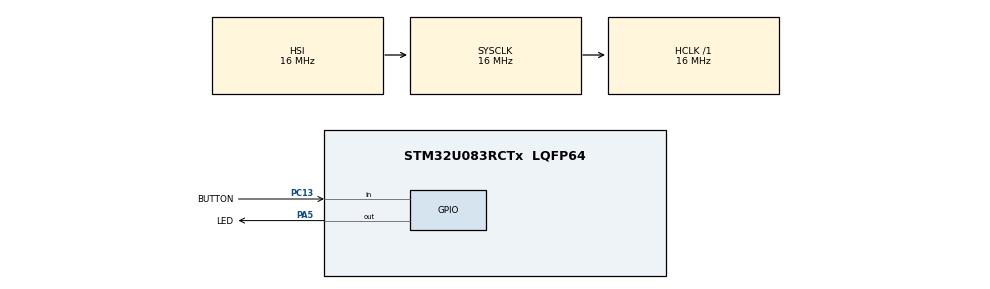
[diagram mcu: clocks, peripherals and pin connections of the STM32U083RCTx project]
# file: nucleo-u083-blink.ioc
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Mcu.Family=STM32U0
Mcu.Name=STM32U083RCTx
Mcu.Package=LQFP64
NVIC.PriorityGroup=NVIC_PRIORITYGROUP_2
PA5.GPIO_Label=LED
PA5.Signal=GPIO_Output
PC13.GPIO_Label=BUTTON
PC13.GPIO_PuPd=GPIO_PULLUP
PC13.Signal=GPIO_Input
ProjectManager.HeapSize=0x200
ProjectManager.StackSize=0x400
ProjectManager.TargetToolchain=Makefile
RCC.AHBFreq_Value=16000000
RCC.CortexFreq_Value=16000000
RCC.HCLKFreq_Value=16000000
RCC.HSE_VALUE=4000000
RCC.HSI48_VALUE=48000000
RCC.HSI_VALUE=16000000
RCC.LSE_VALUE=32768
RCC.MSI_VALUE=4000000
RCC.SYSCLKFreq_VALUE=16000000
RCC.VCOOutputFreq_Value=64000000
VP_PWR_VS_SECSignals.Mode=Security/Privilege
board=custom

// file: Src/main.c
/* USER CODE BEGIN Header */
/**
 ******************************************************************************
 * @file           : main.c
 * @brief          : Main program body
 ******************************************************************************
 * @attention
 *
 * Copyright (c) 2025 STMicroelectronics.
 * All rights reserved.
 *
 * This software is licensed under terms that can be found in the LICENSE file
 * in the root directory of this software component.
 * If no LICENSE file comes with this software, it is provided AS-IS.
 *
 ******************************************************************************
 */
/* USER CODE END Header */
#include "main.h"

#include "gpio.h"

/* USER CODE BEGIN Includes */
#include <stdbool.h>

/* USER CODE END Includes */

void SystemClock_Config(void);

int main(void) {

    /* MCU
     * Configuration--------------------------------------------------------*/

    /* Reset of all peripherals, Initializes the Flash interface and the
     * Systick. */
    HAL_Init();

    /* Configure the system clock */
    SystemClock_Config();

    /* Initialize all configured peripherals */
    MX_GPIO_Init();

    /* Infinite loop */
    while (1) {

        /* USER CODE BEGIN 3 */
        bool blink_faster = !HAL_GPIO_ReadPin(BUTTON_GPIO_Port, BUTTON_Pin);
        HAL_GPIO_TogglePin(LED_GPIO_Port, LED_Pin);
        HAL_Delay(blink_faster ? 100 : 250);
    }
    /* USER CODE END 3 */
}

void SystemClock_Config(void) {
    RCC_OscInitTypeDef RCC_OscInitStruct = {0};
    RCC_ClkInitTypeDef RCC_ClkInitStruct = {0};

    /** Configure the main internal regulator output voltage
     */
    HAL_PWREx_ControlVoltageScaling(PWR_REGULATOR_VOLTAGE_SCALE2);

    /** Initializes the RCC Oscillators according to the specified parameters
     * in the RCC_OscInitTypeDef structure.
     */
    RCC_OscInitStruct.OscillatorType = RCC_OSCILLATORTYPE_HSI;
    RCC_OscInitStruct.HSIState = RCC_HSI_ON;
    RCC_OscInitStruct.HSICalibrationValue = RCC_HSICALIBRATION_DEFAULT;
    RCC_OscInitStruct.PLL.PLLState = RCC_PLL_NONE;
    if (HAL_RCC_OscConfig(&RCC_OscInitStruct) != HAL_OK) {
        Error_Handler();
    }

    /** Initializes the CPU, AHB and APB buses clocks
     */
    RCC_ClkInitStruct.ClockType =
        RCC_CLOCKTYPE_HCLK | RCC_CLOCKTYPE_SYSCLK | RCC_CLOCKTYPE_PCLK1;
    RCC_ClkInitStruct.SYSCLKSource = RCC_SYSCLKSOURCE_HSI;
    RCC_ClkInitStruct.AHBCLKDivider = RCC_SYSCLK_DIV1;
    RCC_ClkInitStruct.APB1CLKDivider = RCC_HCLK_DIV1;

    if (HAL_RCC_ClockConfig(&RCC_ClkInitStruct, FLASH_LATENCY_1) != HAL_OK) {
        Error_Handler();
    }
}

void Error_Handler(void) {
    /* USER CODE BEGIN Error_Handler_Debug */
    /* User can add his own implementation to report the HAL error return state
     */
    __disable_irq();
    while (1) {
    }
    /* USER CODE END Error_Handler_Debug */
}
#ifdef USE_FULL_ASSERT
/**
 * @brief  Reports the name of the source file and the source line number
 *         where the assert_param error has occurred.
 * @param  file: pointer to the source file name
 * @param  line: assert_param error line source number
 * @retval None
 */
void assert_failed(uint8_t* file, uint32_t line) {
    /* USER CODE BEGIN 6 */
    /* User can add his own implementation to report the file name and line
       number, ex: printf("Wrong parameters value: file %s on line %d\r\n",
       file, line) */
    /* USER CODE END 6 */
}
#endif /* USE_FULL_ASSERT */
